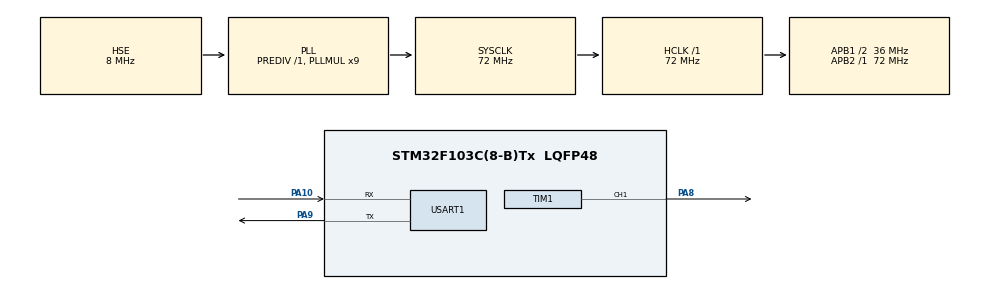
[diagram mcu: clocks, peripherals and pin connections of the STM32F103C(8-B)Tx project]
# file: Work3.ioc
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Mcu.Family=STM32F1
Mcu.Name=STM32F103C(8-B)Tx
Mcu.Package=LQFP48
NVIC.PriorityGroup=NVIC_PRIORITYGROUP_4
NVIC.USART1_IRQn=true\:0\:0\:false\:false\:true\:true\:true\:true
PA10.Mode=Asynchronous
PA10.Signal=USART1_RX
PA13.Mode=Serial_Wire
PA13.Signal=SYS_JTMS-SWDIO
PA14.Mode=Serial_Wire
PA14.Signal=SYS_JTCK-SWCLK
PA8.Signal=S_TIM1_CH1
PA9.Mode=Asynchronous
PA9.Signal=USART1_TX
PD0-OSC_IN.Mode=HSE-External-Oscillator
PD0-OSC_IN.Signal=RCC_OSC_IN
PD1-OSC_OUT.Mode=HSE-External-Oscillator
PD1-OSC_OUT.Signal=RCC_OSC_OUT
ProjectManager.HeapSize=0x200
ProjectManager.StackSize=0x400
ProjectManager.TargetToolchain=MDK-ARM V5.32
RCC.AHBFreq_Value=72000000
RCC.APB1CLKDivider=RCC_HCLK_DIV2
RCC.APB1Freq_Value=36000000
RCC.APB1TimFreq_Value=72000000
RCC.APB2Freq_Value=72000000
RCC.APB2TimFreq_Value=72000000
RCC.HCLKFreq_Value=72000000
RCC.PLLMUL=RCC_PLL_MUL9
RCC.PLLSourceVirtual=RCC_PLLSOURCE_HSE
RCC.SYSCLKFreq_VALUE=72000000
RCC.SYSCLKSource=RCC_SYSCLKSOURCE_PLLCLK
RCC.USBFreq_Value=72000000
SH.S_TIM1_CH1.0=TIM1_CH1,PWM Generation1 CH1
TIM1.Channel-PWM\ Generation1\ CH1=TIM_CHANNEL_1
TIM1.Period=7200-1
TIM1.Pulse-PWM\ Generation1\ CH1=20
USART1.VirtualMode=VM_ASYNC
VP_TIM1_VS_ClockSourceINT.Mode=Internal
board=custom

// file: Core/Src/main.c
/* USER CODE BEGIN Header */
/**
  ******************************************************************************
  * @file           : main.c
  * @brief          : Main program body
  ******************************************************************************
  * @attention
  *
  * Copyright (c) 2024 STMicroelectronics.
  * All rights reserved.
  *
  * This software is licensed under terms that can be found in the LICENSE file
  * in the root directory of this software component.
  * If no LICENSE file comes with this software, it is provided AS-IS.
  *
  ******************************************************************************
  */
/* USER CODE END Header */
#include "main.h"
#include "tim.h"
#include "usart.h"
#include "gpio.h"

/* USER CODE BEGIN Includes */
#include "string.h"                  //包含了字符串处理
#include "stdio.h"                  //包含了标准输入输出
#include "stdlib.h"                 //包含了标准库函数
/* USER CODE END Includes */

/* USER CODE BEGIN PV */
#define Rx_Buffer_Size 10       // 接收缓冲区大小
char RxBuffer[Rx_Buffer_Size];  // 定义字符接收缓冲区
uint8_t RxFlag = 0;            // 接收标志位，初始化为0
/* USER CODE END PV */

void SystemClock_Config(void);
/* USER CODE BEGIN PFP */

/* UART接收回调函数 */
void HAL_UARTEx_RxEventCallback(UART_HandleTypeDef *huart, uint16_t Size)
{
    if (huart == &huart1)        // 检查是否是目标UART
    {
        RxBuffer[Size] = '\0';   // 添加字符串结束符以标识字符串结束
        int receiveValue = atoi(RxBuffer); // 将接收到的字符串转换为整数
        /* 检查接收到的数值是否在有效范围内 */
        if (receiveValue >=0 && receiveValue <= 7199)
        {
            __HAL_TIM_SET_COMPARE(&htim1, TIM_CHANNEL_1, 7199-receiveValue);  // 设置PWM比较值
            RxFlag = 1;       // 设置接收标志
        }
        else                 // 如果数值不在范围内
        {
            /*  发送错误提示信息 */
            HAL_UART_Transmit(&huart1, (uint8_t *)"report errors! Please enter a numerical value in the range of 0-7199\r\n",70,1000);
            RxFlag = 0;     // 清除接收标志
        }
        HAL_UARTEx_ReceiveToIdle_IT(&huart1, (uint8_t *)RxBuffer, Rx_Buffer_Size); // 重新启动接收
    }
}
/* USER CODE END PFP */

int main(void)
{

  /* MCU Configuration--------------------------------------------------------*/

  /* Reset of all peripherals, Initializes the Flash interface and the Systick. */
  HAL_Init();

  /* Configure the system clock */
  SystemClock_Config();

  /* Initialize all configured peripherals */
  MX_GPIO_Init();
  MX_TIM1_Init();
  MX_USART1_UART_Init();
  /* USER CODE BEGIN 2 */
  HAL_TIM_PWM_Start(&htim1,TIM_CHANNEL_1);      // 启动PWM
  HAL_UARTEx_ReceiveToIdle_IT(&huart1,(uint8_t *)RxBuffer,Rx_Buffer_Size);  // 开始接收数据
  /* USER CODE END 2 */

  /* Infinite loop */
  while (1)
  {

    /* USER CODE BEGIN 3 */
      if (RxFlag == 1)       // 检查是否接收到有效数据
      {
          /* 将接收到的数据发送回去 */
        HAL_UART_Transmit(&huart1, (uint8_t *)RxBuffer, strlen(RxBuffer), HAL_MAX_DELAY);
        RxFlag =0;          // 重置接收标志，准备接收新的数据
      }
  }
  /* USER CODE END 3 */
}

void SystemClock_Config(void)
{
  RCC_OscInitTypeDef RCC_OscInitStruct = {0};
  RCC_ClkInitTypeDef RCC_ClkInitStruct = {0};

  /** Initializes the RCC Oscillators according to the specified parameters
  * in the RCC_OscInitTypeDef structure.
  */
  RCC_OscInitStruct.OscillatorType = RCC_OSCILLATORTYPE_HSE;
  RCC_OscInitStruct.HSEState = RCC_HSE_ON;
  RCC_OscInitStruct.HSEPredivValue = RCC_HSE_PREDIV_DIV1;
  RCC_OscInitStruct.HSIState = RCC_HSI_ON;
  RCC_OscInitStruct.PLL.PLLState = RCC_PLL_ON;
  RCC_OscInitStruct.PLL.PLLSource = RCC_PLLSOURCE_HSE;
  RCC_OscInitStruct.PLL.PLLMUL = RCC_PLL_MUL9;
  if (HAL_RCC_OscConfig(&RCC_OscInitStruct) != HAL_OK)
  {
    Error_Handler();
  }

  /** Initializes the CPU, AHB and APB buses clocks
  */
  RCC_ClkInitStruct.ClockType = RCC_CLOCKTYPE_HCLK|RCC_CLOCKTYPE_SYSCLK
                              |RCC_CLOCKTYPE_PCLK1|RCC_CLOCKTYPE_PCLK2;
  RCC_ClkInitStruct.SYSCLKSource = RCC_SYSCLKSOURCE_PLLCLK;
  RCC_ClkInitStruct.AHBCLKDivider = RCC_SYSCLK_DIV1;
  RCC_ClkInitStruct.APB1CLKDivider = RCC_HCLK_DIV2;
  RCC_ClkInitStruct.APB2CLKDivider = RCC_HCLK_DIV1;

  if (HAL_RCC_ClockConfig(&RCC_ClkInitStruct, FLASH_LATENCY_2) != HAL_OK)
  {
    Error_Handler();
  }
}

void Error_Handler(void)
{
  __disable_irq();
  while (1)
  {
  }
}
